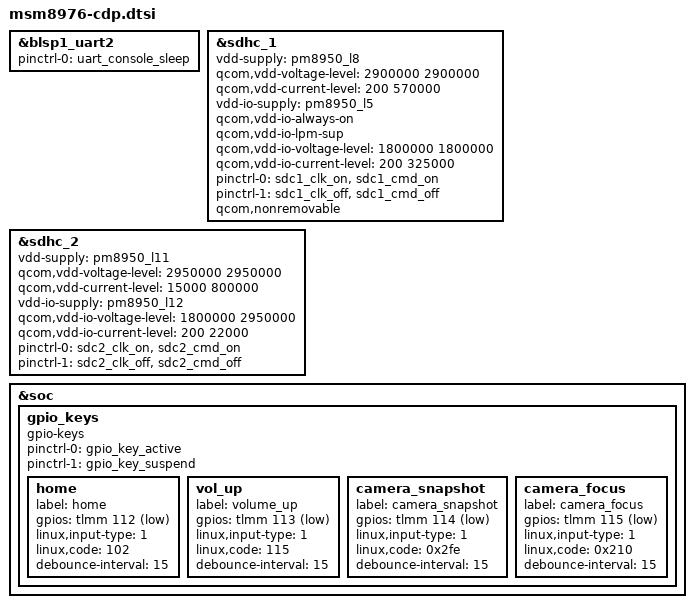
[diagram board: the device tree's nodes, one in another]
// SPDX-License-Identifier: GPL-2.0
// Copyright (c) 2015, The Linux Foundation. All rights reserved.
// Copyright (c) 2023-2024, Benarji Anand <benarji385@gmail.com>

#include "msm8976-camera-sensor-cdp.dtsi"
#include "msm8976-mdss-cdp.dtsi"

&blsp1_uart2 {
	status = "ok";
	pinctrl-names = "default";
	pinctrl-0 = <&uart_console_sleep>;
};

&sdhc_1 {
	vdd-supply = <&pm8950_l8>;
	qcom,vdd-voltage-level = <2900000 2900000>;
	qcom,vdd-current-level = <200 570000>;

	vdd-io-supply = <&pm8950_l5>;
	qcom,vdd-io-always-on;
	qcom,vdd-io-lpm-sup;
	qcom,vdd-io-voltage-level = <1800000 1800000>;
	qcom,vdd-io-current-level = <200 325000>;

	pinctrl-names = "active", "sleep";
	pinctrl-0 = <&sdc1_clk_on &sdc1_cmd_on>;
	pinctrl-1 = <&sdc1_clk_off &sdc1_cmd_off>;

	qcom,nonremovable;

	status = "ok";
};

&sdhc_2 {
	vdd-supply = <&pm8950_l11>;
	qcom,vdd-voltage-level = <2950000 2950000>;
	qcom,vdd-current-level = <15000 800000>;

	vdd-io-supply = <&pm8950_l12>;
	qcom,vdd-io-voltage-level = <1800000 2950000>;
	qcom,vdd-io-current-level = <200 22000>;

	pinctrl-names = "active", "sleep";
	pinctrl-0 = <&sdc2_clk_on &sdc2_cmd_on>;
	pinctrl-1 = <&sdc2_clk_off &sdc2_cmd_off>;

	status = "ok";
};

&soc {
	gpio_keys {
		compatible = "gpio-keys";
		pinctrl-names = "tlmm_gpio_key_active","tlmm_gpio_key_suspend";
		pinctrl-0 = <&gpio_key_active>;
		pinctrl-1 = <&gpio_key_suspend>;

		home {
			label = "home";
			gpios = <&tlmm 112 0x1>;
			linux,input-type = <1>;
			linux,code = <102>;
			debounce-interval = <15>;
		};

		vol_up {
			label = "volume_up";
			gpios = <&tlmm 113 0x1>;
			linux,input-type = <1>;
			linux,code = <115>;
			debounce-interval = <15>;
		};

		camera_snapshot {
			label = "camera_snapshot";
			gpios = <&tlmm 114 0x1>;
			linux,input-type = <1>;
			linux,code = <0x2fe>;
			debounce-interval = <15>;
		};

		camera_focus {
			label = "camera_focus";
			gpios = <&tlmm 115 0x1>;
			linux,input-type = <1>;
			linux,code = <0x210>;
			debounce-interval = <15>;
		};
	};
};
